# APM32F091 register map
File version: 1.0
Registers are 32-bit, read-write, reset 0x0 unless marked. A register's access mark holds for its fields unless they carry their own. Offsets are from the block's base; [hi:lo] are bit positions; {n}, {i} and the like mark numbered series.

## RCM — Reset and clock control
Base 0x40021000
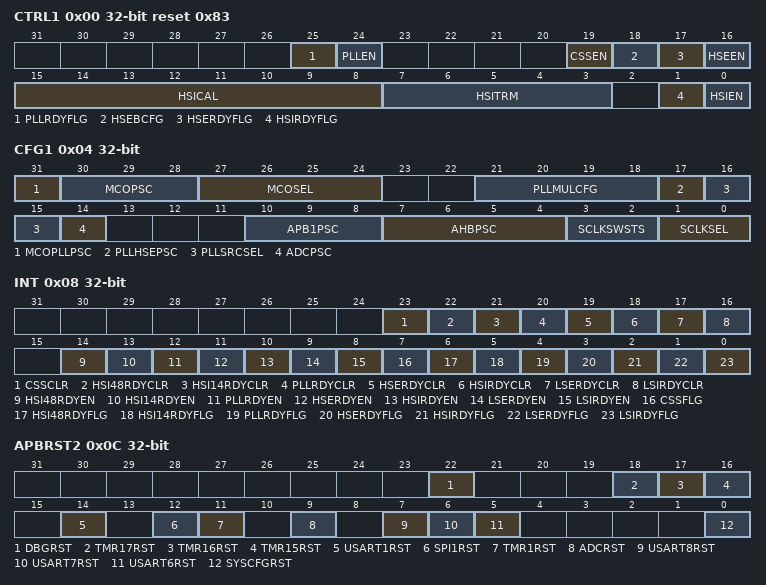
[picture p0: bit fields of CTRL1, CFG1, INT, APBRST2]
0x00 CTRL1 access per field reset 0x83 — Clock control register 1
  [25] PLLRDYFLG ro — PLL clock ready flag
  [24] PLLEN rw — PLL enable
  [19] CSSEN rw — Clock Security System enable
  [18] HSEBCFG rw — External High Speed clock Bypass
  [17] HSERDYFLG ro — External High Speed clock ready flag
  [16] HSEEN rw — External High Speed clock enable
  [15:8] HSICAL ro — Internal High Speed clock Calibration
  [7:3] HSITRM rw — Internal High Speed clock trimming
  [1] HSIRDYFLG ro — Internal High Speed clock ready flag
  [0] HSIEN rw — Internal High Speed clock enable
0x04 CFG1 access per field — Clock configuration register 1
  [31] MCOPLLPSC rw — PLL clock not divided for COC
  [30:28] MCOPSC rw — Microcontroller Clock Output divide
  [27:24] MCOSEL rw — Microcontroller clock output
  [21:18] PLLMULCFG rw — PLL Multiplication Factor
  [17] PLLHSEPSC rw — HXT divider for PLL entry
  [16:15] PLLSRCSEL rw — PLL input clock source
  [14] ADCPSC rw — ADC prescaler
  [10:8] APB1PSC rw — APB Low speed prescaler
  [7:4] AHBPSC rw — AHB prescaler
  [3:2] SCLKSWSTS ro — System Clock Switch Status
  [1:0] SCLKSEL rw — System clock Switch
0x08 INT access per field — Clock interrupt register
  [23] CSSCLR wo — Clock security system interrupt clear
  [22] HSI48RDYCLR wo — HIRC48 Ready Interrupt Clear
  [21] HSI14RDYCLR wo — HIRC 14 MHz Ready Interrupt Clear
  [20] PLLRDYCLR wo — PLL Ready Interrupt Clear
  [19] HSERDYCLR wo — HXT Ready Interrupt Clear
  [18] HSIRDYCLR wo — HIRC Ready Interrupt Clear
  [17] LSERDYCLR wo — LXT Ready Interrupt Clear
  [16] LSIRDYCLR wo — LIRC Ready Interrupt Clear
  [14] HSI48RDYEN rw — HIRC48 ready interrupt enable
  [13] HSI14RDYEN rw — HIRC14 ready interrupt enable
  [12] PLLRDYEN rw — PLL Ready Interrupt Enable
  [11] HSERDYEN rw — HXT Ready Interrupt Enable
  [10] HSIRDYEN rw — HIRC Ready Interrupt Enable
  [9] LSERDYEN rw — LXT Ready Interrupt Enable
  [8] LSIRDYEN rw — LIRC Ready Interrupt Enable
  [7] CSSFLG ro — Clock Security System Interrupt flag
  [6] HSI48RDYFLG ro — HIRC48 ready interrupt flag
  [5] HSI14RDYFLG ro — HIRC14 ready interrupt flag
  [4] PLLRDYFLG ro — PLL Ready Interrupt flag
  [3] HSERDYFLG ro — HXT Ready Interrupt flag
  [2] HSIRDYFLG ro — HIRC Ready Interrupt flag
  [1] LSERDYFLG ro — LXT Ready Interrupt flag
  [0] LSIRDYFLG ro — LIRC Ready Interrupt flag
0x0C APBRST2 — APB2 peripheral reset register
  [22] DBGRST — Debug MCU reset
  [18] TMR17RST — TMR17 timer reset
  [17] TMR16RST — TMR16 timer reset
  [16] TMR15RST — TMR15 timer reset
  [14] USART1RST — USART1 reset
  [12] SPI1RST — SPI 1 reset
  [11] TMR1RST — TMR1 timer reset
  [9] ADCRST — ADC interface reset
  [7] USART8RST — USART8 reset
  [6] USART7RST — USART7 reset
  [5] USART6RST — USART6 reset
  [0] SYSCFGRST — SYSCFG reset
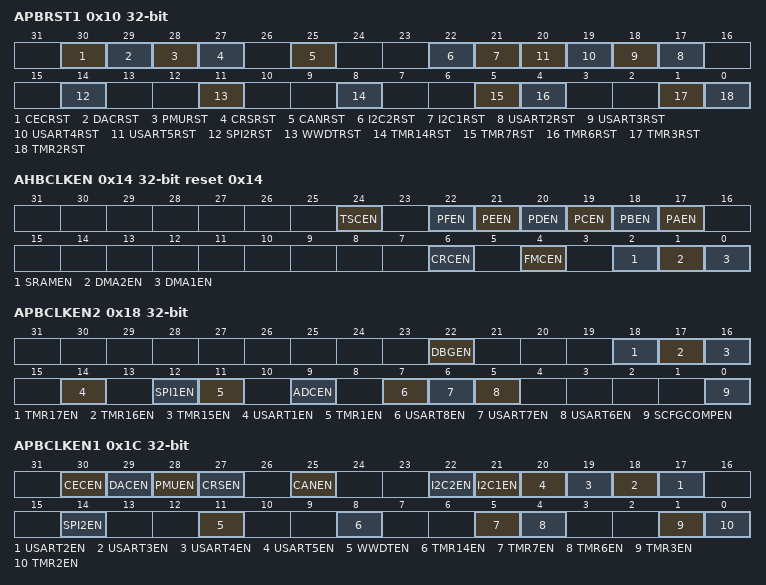
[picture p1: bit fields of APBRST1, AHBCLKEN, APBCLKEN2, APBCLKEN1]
0x10 APBRST1 — APB1 peripheral reset register
  [30] CECRST — CEC reset
  [29] DACRST — DAC reset
  [28] PMURST — PMU reset
  [27] CRSRST — CRS reset
  [25] CANRST — CAN reset
  [22] I2C2RST — I2C2 reset
  [21] I2C1RST — I2C1 reset
  [n+15] USART{n}RST (n=2..5) — USART {n} reset
  [14] SPI2RST — SPI2 reset
  [11] WWDTRST — Window watchdog reset
  [8] TMR14RST — Timer 14 reset
  [5] TMR7RST — Timer 7 reset
  [4] TMR6RST — Timer 6 reset
  [1] TMR3RST — Timer 3 reset
  [0] TMR2RST — Timer 2 reset
0x14 AHBCLKEN reset 0x14 — AHB Peripheral Clock enable register
  [24] TSCEN — Touch sensing controller clock enable
  [22] PFEN — I/O port F clock enable
  [21] PEEN — I/O port E clock enable
  [20] PDEN — I/O port D clock enable
  [19] PCEN — I/O port C clock enable
  [18] PBEN — I/O port B clock enable
  [17] PAEN — I/O port A clock enable
  [6] CRCEN — CRC clock enable
  [4] FMCEN — FLITF clock enable
  [2] SRAMEN — SRAM interface clock enable
  [1] DMA2EN — DMA1 clock enable
  [0] DMA1EN — DMA1 clock enable
0x18 APBCLKEN2 — APB2 peripheral clock enable register
  [22] DBGEN — MCU debug module clock enable
  [18] TMR17EN — TMR17 timer clock enable
  [17] TMR16EN — TMR16 timer clock enable
  [16] TMR15EN — TMR15 timer clock enable
  [14] USART1EN — USART1 clock enable
  [12] SPI1EN — SPI 1 clock enable
  [11] TMR1EN — TMR1 Timer clock enable
  [9] ADCEN — ADC 1 interface clock enable
  [7] USART8EN — USART8 enable
  [6] USART7EN — USART7 enable
  [5] USART6EN — USART6 enable
  [0] SCFGCOMPEN — SYSCFG and COMP clock enable
0x1C APBCLKEN1 — APB1 peripheral clock enable register
  [30] CECEN — CEC clock enable
  [29] DACEN — DAC clock enable
  [28] PMUEN — PMU clock enable
  [27] CRSEN — CRS clock enable
  [25] CANEN — CAN clock enable
  [22] I2C2EN — I2C 2 clock enable
  [21] I2C1EN — I2C 1 clock enable
  [n+15] USART{n}EN (n=2..5) — USART {n} clock enable
  [14] SPI2EN — SPI 2 clock enable
  [11] WWDTEN — Window watchdog clock enable
  [8] TMR14EN — Timer 14 clock enable
  [5] TMR7EN — Timer 7 clock enable
  [4] TMR6EN — Timer 6 clock enable
  [1] TMR3EN — Timer 3 clock enable
  [0] TMR2EN — Timer 2 clock enable
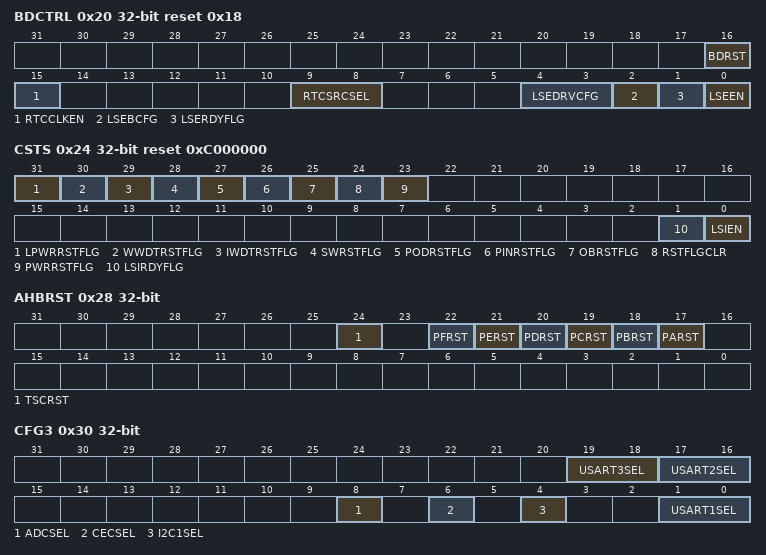
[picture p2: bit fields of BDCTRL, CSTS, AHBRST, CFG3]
0x20 BDCTRL access per field reset 0x18 — Backup domain control register
  [16] BDRST rw — Backup domain software reset
  [15] RTCCLKEN rw — RTC clock enable
  [9:8] RTCSRCSEL rw — RTC clock source selection
  [4:3] LSEDRVCFG rw — LXT oscillator drive capability
  [2] LSEBCFG rw — External Low Speed oscillator bypass
  [1] LSERDYFLG ro — External Low Speed oscillator ready
  [0] LSEEN rw — External Low Speed oscillator enable
0x24 CSTS access per field reset 0xC000000 — Control/status register
  [31] LPWRRSTFLG ro — Low-power reset flag
  [30] WWDTRSTFLG ro — Window watchdog reset flag
  [29] IWDTRSTFLG ro — Independent watchdog reset flag
  [28] SWRSTFLG ro — Software reset flag
  [27] PODRSTFLG ro — POR/PDR reset flag
  [26] PINRSTFLG ro — PIN reset flag
  [25] OBRSTFLG ro — Option byte loader reset flag
  [24] RSTFLGCLR rw — Remove reset flag
  [23] PWRRSTFLG ro — Reset Flag of The 1.5V Domain
  [1] LSIRDYFLG ro — Internal low speed oscillator ready
  [0] LSIEN rw — Internal low speed oscillator enable
0x28 AHBRST — AHB peripheral reset register
  [24] TSCRST — Touch sensing controller reset
  [22] PFRST — I/O port F reset
  [21] PERST — I/O port E reset
  [20] PDRST — I/O port D reset
  [19] PCRST — I/O port C reset
  [18] PBRST — I/O port B reset
  [17] PARST — I/O port A reset
0x2C CFG2 — Clock configuration register 2
  [3:0] PLLDIVCFG — CLKDIV division factor
0x30 CFG3 — Clock configuration register 3
  [19:18] USART3SEL — USART3 clock source selection
  [17:16] USART2SEL — USART2 clock source selection
  [8] ADCSEL — ADC clock source selection
  [6] CECSEL — CEC clock source selection
  [4] I2C1SEL — I2C1 clock source selection
  [1:0] USART1SEL — USART1 clock source selection
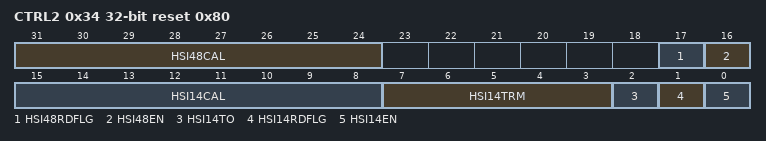
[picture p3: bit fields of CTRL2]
0x34 CTRL2 access per field reset 0x80 — Clock control register 2
  [31:24] HSI48CAL ro — HIRC48 factory clock calibration
  [17] HSI48RDFLG ro — HIRC48 clock ready flag
  [16] HSI48EN rw — HIRC48 clock enable
  [15:8] HSI14CAL ro — HIRC14 clock calibration
  [7:3] HSI14TRM rw — HIRC14 clock trimming
  [2] HSI14TO rw — HIRC14 clock request from ADC disable
  [1] HSI14RDFLG ro — HIRC14 clock ready flag
  [0] HSI14EN rw — HIRC14 clock enable
